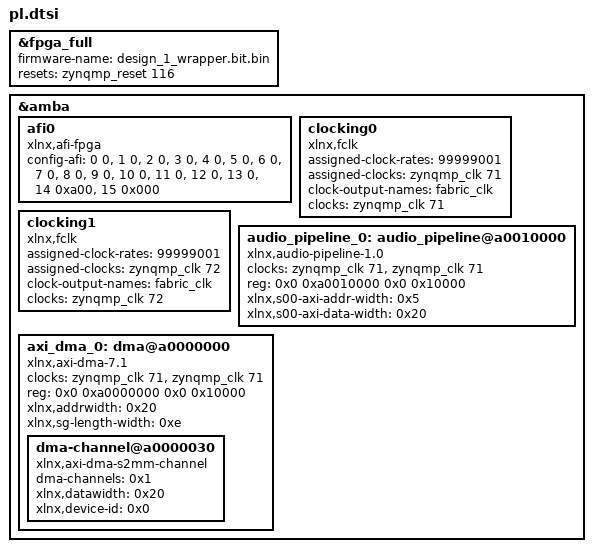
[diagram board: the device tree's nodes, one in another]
/*
 * CAUTION: This file is automatically generated by Xilinx.
 * Version: XSCT 2021.2
 * Today is: Sat Oct 21 21:18:51 2023
 */


/dts-v1/;
/plugin/;
/ {
	fragment@0 {
		target = <&fpga_full>;
		overlay0: __overlay__ {
			#address-cells = <2>;
			#size-cells = <2>;
			firmware-name = "design_1_wrapper.bit.bin";
			resets = <&zynqmp_reset 116>;
		};
	};
	fragment@1 {
		target = <&amba>;
		overlay1: __overlay__ {
			afi0: afi0 {
				compatible = "xlnx,afi-fpga";
				config-afi = < 0 0>, <1 0>, <2 0>, <3 0>, <4 0>, <5 0>, <6 0>, <7 0>, <8 0>, <9 0>, <10 0>, <11 0>, <12 0>, <13 0>, <14 0xa00>, <15 0x000>;
			};
			clocking0: clocking0 {
				#clock-cells = <0>;
				assigned-clock-rates = <99999001>;
				assigned-clocks = <&zynqmp_clk 71>;
				clock-output-names = "fabric_clk";
				clocks = <&zynqmp_clk 71>;
				compatible = "xlnx,fclk";
			};
			clocking1: clocking1 {
				#clock-cells = <0>;
				assigned-clock-rates = <99999001>;
				assigned-clocks = <&zynqmp_clk 72>;
				clock-output-names = "fabric_clk";
				clocks = <&zynqmp_clk 72>;
				compatible = "xlnx,fclk";
			};
		};
	};
	fragment@2 {
		target = <&amba>;
		overlay2: __overlay__ {
			#address-cells = <2>;
			#size-cells = <2>;
			audio_pipeline_0: audio_pipeline@a0010000 {
				/* This is a place holder node for a custom IP, user may need to update the entries */
				clock-names = "clk", "s00_axi_aclk";
				clocks = <&zynqmp_clk 71>, <&zynqmp_clk 71>;
				compatible = "xlnx,audio-pipeline-1.0";
				reg = <0x0 0xa0010000 0x0 0x10000>;
				xlnx,s00-axi-addr-width = <0x5>;
				xlnx,s00-axi-data-width = <0x20>;
			};
			axi_dma_0: dma@a0000000 {
				#dma-cells = <1>;
				clock-names = "s_axi_lite_aclk", "m_axi_s2mm_aclk";
				clocks = <&zynqmp_clk 71>, <&zynqmp_clk 71>;
				compatible = "xlnx,axi-dma-7.1", "xlnx,axi-dma-1.00.a";
				reg = <0x0 0xa0000000 0x0 0x10000>;
				xlnx,addrwidth = <0x20>;
				xlnx,sg-length-width = <0xe>;
				dma-channel@a0000030 {
					compatible = "xlnx,axi-dma-s2mm-channel";
					dma-channels = <0x1>;
					xlnx,datawidth = <0x20>;
					xlnx,device-id = <0x0>;
				};
			};
		};
	};
};
